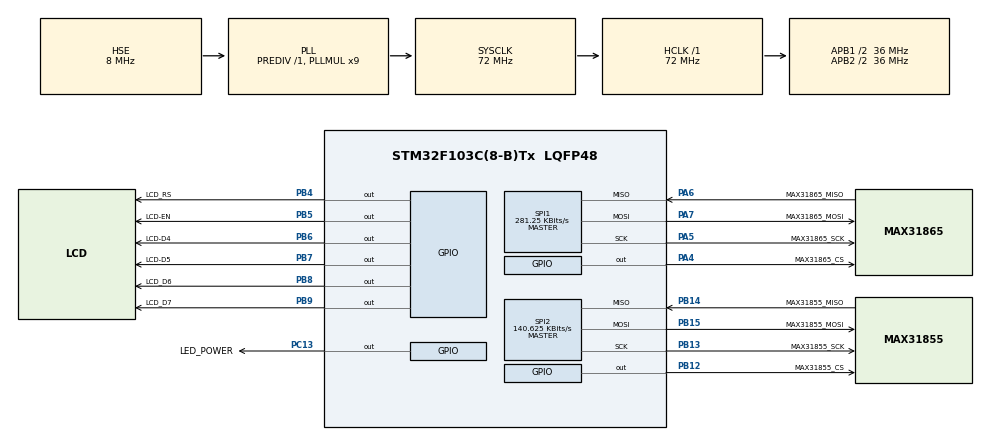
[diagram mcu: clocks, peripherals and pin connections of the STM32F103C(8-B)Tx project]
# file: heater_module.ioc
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Dma.Request0=SPI1_RX
Dma.Request1=SPI1_TX
Dma.Request2=SPI2_RX
Dma.Request3=SPI2_TX
Dma.SPI1_RX.0.Direction=DMA_PERIPH_TO_MEMORY
Dma.SPI1_RX.0.Instance=DMA1_Channel2
Dma.SPI1_RX.0.MemDataAlignment=DMA_MDATAALIGN_BYTE
Dma.SPI1_RX.0.MemInc=DMA_MINC_ENABLE
Dma.SPI1_RX.0.Mode=DMA_NORMAL
Dma.SPI1_RX.0.PeriphDataAlignment=DMA_PDATAALIGN_BYTE
Dma.SPI1_RX.0.PeriphInc=DMA_PINC_DISABLE
Dma.SPI1_RX.0.Priority=DMA_PRIORITY_LOW
Dma.SPI1_TX.1.Direction=DMA_MEMORY_TO_PERIPH
Dma.SPI1_TX.1.Instance=DMA1_Channel3
Dma.SPI1_TX.1.MemDataAlignment=DMA_MDATAALIGN_BYTE
Dma.SPI1_TX.1.MemInc=DMA_MINC_ENABLE
Dma.SPI1_TX.1.Mode=DMA_NORMAL
Dma.SPI1_TX.1.PeriphDataAlignment=DMA_PDATAALIGN_BYTE
Dma.SPI1_TX.1.PeriphInc=DMA_PINC_DISABLE
Dma.SPI1_TX.1.Priority=DMA_PRIORITY_LOW
Dma.SPI2_RX.2.Direction=DMA_PERIPH_TO_MEMORY
Dma.SPI2_RX.2.Instance=DMA1_Channel4
Dma.SPI2_RX.2.MemDataAlignment=DMA_MDATAALIGN_BYTE
Dma.SPI2_RX.2.MemInc=DMA_MINC_ENABLE
Dma.SPI2_RX.2.Mode=DMA_NORMAL
Dma.SPI2_RX.2.PeriphDataAlignment=DMA_PDATAALIGN_BYTE
Dma.SPI2_RX.2.PeriphInc=DMA_PINC_DISABLE
Dma.SPI2_RX.2.Priority=DMA_PRIORITY_LOW
Dma.SPI2_TX.3.Direction=DMA_MEMORY_TO_PERIPH
Dma.SPI2_TX.3.Instance=DMA1_Channel5
Dma.SPI2_TX.3.MemDataAlignment=DMA_MDATAALIGN_BYTE
Dma.SPI2_TX.3.MemInc=DMA_MINC_ENABLE
Dma.SPI2_TX.3.Mode=DMA_NORMAL
Dma.SPI2_TX.3.PeriphDataAlignment=DMA_PDATAALIGN_BYTE
Dma.SPI2_TX.3.PeriphInc=DMA_PINC_DISABLE
Dma.SPI2_TX.3.Priority=DMA_PRIORITY_LOW
Mcu.Family=STM32F1
Mcu.Name=STM32F103C(8-B)Tx
Mcu.Package=LQFP48
NVIC.DMA1_Channel2_IRQn=true\:9\:0\:true\:false\:true\:false\:true\:true
NVIC.DMA1_Channel3_IRQn=true\:13\:0\:true\:false\:true\:false\:true\:true
NVIC.DMA1_Channel4_IRQn=true\:9\:0\:true\:false\:true\:false\:true\:true
NVIC.DMA1_Channel5_IRQn=true\:0\:0\:false\:false\:true\:false\:true\:true
NVIC.PriorityGroup=NVIC_PRIORITYGROUP_4
NVIC.SPI1_IRQn=true\:0\:0\:false\:false\:true\:true\:true\:true
NVIC.SPI2_IRQn=true\:0\:0\:false\:false\:true\:true\:true\:true
NVIC.TIM1_UP_IRQn=true\:0\:0\:false\:false\:true\:true\:true\:true
PA4.GPIO_Label=MAX31865_CS
PA4.Signal=GPIO_Output
PA5.GPIO_Label=MAX31865_SCK
PA5.Mode=Full_Duplex_Master
PA5.Signal=SPI1_SCK
PA6.GPIO_Label=MAX31865_MISO
PA6.Mode=Full_Duplex_Master
PA6.Signal=SPI1_MISO
PA7.GPIO_Label=MAX31865_MOSI
PA7.Mode=Full_Duplex_Master
PA7.Signal=SPI1_MOSI
PB12.GPIO_Label=MAX31855_CS
PB12.Signal=GPIO_Output
PB13.GPIO_Label=MAX31855_SCK
PB13.Mode=Full_Duplex_Master
PB13.Signal=SPI2_SCK
PB14.GPIO_Label=MAX31855_MISO
PB14.Mode=Full_Duplex_Master
PB14.Signal=SPI2_MISO
PB15.GPIO_Label=MAX31855_MOSI
PB15.Mode=Full_Duplex_Master
PB15.Signal=SPI2_MOSI
PB4.GPIO_Label=LCD_RS
PB4.Signal=GPIO_Output
PB5.GPIO_Label=LCD-EN
PB5.Signal=GPIO_Output
PB6.GPIO_Label=LCD-D4
PB6.Signal=GPIO_Output
PB7.GPIO_Label=LCD-D5
PB7.Signal=GPIO_Output
PB8.GPIO_Label=LCD_D6
PB8.Signal=GPIO_Output
PB9.GPIO_Label=LCD_D7
PB9.Signal=GPIO_Output
PC13-TAMPER-RTC.GPIO_Label=LED_POWER
PC13-TAMPER-RTC.Signal=GPIO_Output
PD0-OSC_IN.Mode=HSE-External-Oscillator
PD0-OSC_IN.Signal=RCC_OSC_IN
PD1-OSC_OUT.Mode=HSE-External-Oscillator
PD1-OSC_OUT.Signal=RCC_OSC_OUT
ProjectManager.HeapSize=0x200
ProjectManager.StackSize=0x400
ProjectManager.TargetToolchain=CMake
RCC.ADCPresc=RCC_ADCPCLK2_DIV6
RCC.AHBFreq_Value=72000000
RCC.APB1CLKDivider=RCC_HCLK_DIV2
RCC.APB1Freq_Value=36000000
RCC.APB1TimFreq_Value=72000000
RCC.APB2CLKDivider=RCC_HCLK_DIV2
RCC.APB2Freq_Value=36000000
RCC.APB2TimFreq_Value=72000000
RCC.HCLKFreq_Value=72000000
RCC.PLLMUL=RCC_PLL_MUL9
RCC.PLLSourceVirtual=RCC_PLLSOURCE_HSE
RCC.SYSCLKFreq_VALUE=72000000
RCC.SYSCLKSource=RCC_SYSCLKSOURCE_PLLCLK
RCC.USBFreq_Value=48000000
RCC.USBPrescaler=RCC_USBCLKSOURCE_PLL_DIV1_5
SPI1.BaudRatePrescaler=SPI_BAUDRATEPRESCALER_128
SPI1.CLKPhase=SPI_PHASE_2EDGE
SPI1.CalculateBaudRate=281.25 KBits/s
SPI1.Direction=SPI_DIRECTION_2LINES
SPI1.Mode=SPI_MODE_MASTER
SPI1.VirtualType=VM_MASTER
SPI2.BaudRatePrescaler=SPI_BAUDRATEPRESCALER_256
SPI2.CalculateBaudRate=140.625 KBits/s
SPI2.Direction=SPI_DIRECTION_2LINES
SPI2.Mode=SPI_MODE_MASTER
SPI2.VirtualType=VM_MASTER
TIM1.ClockDivision=TIM_CLOCKDIVISION_DIV4
TIM1.Period=399
TIM1.Prescaler=8999
VP_SYS_VS_ND.Mode=No_Debug
VP_TIM1_VS_ClockSourceINT.Mode=Internal
board=custom

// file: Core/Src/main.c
/* USER CODE BEGIN Header */
/**
  ******************************************************************************
  * @file           : main.c
  * @brief          : Main program body
  ******************************************************************************
  * @attention
  *
  * Copyright (c) 2026 STMicroelectronics.
  * All rights reserved.
  *
  * This software is licensed under terms that can be found in the LICENSE file
  * in the root directory of this software component.
  * If no LICENSE file comes with this software, it is provided AS-IS.
  *
  ******************************************************************************
  */
/* USER CODE END Header */
#include "main.h"
#include "dma.h"
#include "spi.h"
#include "tim.h"
#include "gpio.h"

/* USER CODE BEGIN Includes */
#include "sensing.h"
#include "lcd.h"
#include <stdio.h>
/* USER CODE END Includes */

void SystemClock_Config(void);

int main(void)
{

  /* MCU Configuration--------------------------------------------------------*/

  /* Reset of all peripherals, Initializes the Flash interface and the Systick. */
  HAL_Init();

  /* Configure the system clock */
  SystemClock_Config();

  /* Initialize all configured peripherals */
  MX_GPIO_Init();
  MX_DMA_Init();
  MX_SPI1_Init();
  MX_SPI2_Init();
  MX_TIM1_Init();
  /* USER CODE BEGIN 2 */
  /* Initialize sensors and display */
  sensing_init();
  LCD_Init();

  /* Start sampling timer in interrupt mode */
  HAL_TIM_Base_Start_IT(&htim1);
  HAL_GPIO_WritePin(LED_POWER_GPIO_Port, LED_POWER_Pin, GPIO_PIN_SET);
  /* USER CODE END 2 */

  /* Infinite loop */
  /* USER CODE BEGIN WHILE */

  while (1)
  {
    /* Update display every 1 second */
    HAL_Delay(1000);

    LCD_Clear();

    LCD_Print(max31865_lcd_buffer);
    LCD_SetCursor(1, 0);
    LCD_Print(max31855_lcd_buffer);

    /* USER CODE END WHILE */

  }
}

void SystemClock_Config(void)
{
  RCC_OscInitTypeDef RCC_OscInitStruct = {0};
  RCC_ClkInitTypeDef RCC_ClkInitStruct = {0};

  /** Initializes the RCC Oscillators according to the specified parameters
  * in the RCC_OscInitTypeDef structure.
  */
  RCC_OscInitStruct.OscillatorType = RCC_OSCILLATORTYPE_HSE;
  RCC_OscInitStruct.HSEState = RCC_HSE_ON;
  RCC_OscInitStruct.HSEPredivValue = RCC_HSE_PREDIV_DIV1;
  RCC_OscInitStruct.HSIState = RCC_HSI_ON;
  RCC_OscInitStruct.PLL.PLLState = RCC_PLL_ON;
  RCC_OscInitStruct.PLL.PLLSource = RCC_PLLSOURCE_HSE;
  RCC_OscInitStruct.PLL.PLLMUL = RCC_PLL_MUL9;
  if (HAL_RCC_OscConfig(&RCC_OscInitStruct) != HAL_OK)
  {
    Error_Handler();
  }

  /** Initializes the CPU, AHB and APB buses clocks
  */
  RCC_ClkInitStruct.ClockType = RCC_CLOCKTYPE_HCLK|RCC_CLOCKTYPE_SYSCLK
                              |RCC_CLOCKTYPE_PCLK1|RCC_CLOCKTYPE_PCLK2;
  RCC_ClkInitStruct.SYSCLKSource = RCC_SYSCLKSOURCE_PLLCLK;
  RCC_ClkInitStruct.AHBCLKDivider = RCC_SYSCLK_DIV1;
  RCC_ClkInitStruct.APB1CLKDivider = RCC_HCLK_DIV2;
  RCC_ClkInitStruct.APB2CLKDivider = RCC_HCLK_DIV2;

  if (HAL_RCC_ClockConfig(&RCC_ClkInitStruct, FLASH_LATENCY_2) != HAL_OK)
  {
    Error_Handler();
  }
}

void Error_Handler(void)
{
  __disable_irq();
  while (1)
  {
  }
}
